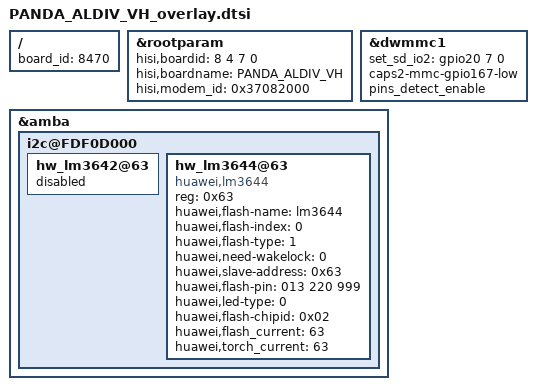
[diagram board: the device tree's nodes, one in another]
/**
 * Copyright (C) 2014 Hisilicon Ltd.
 *
 *  This program is free software; you can redistribute it and/or modify
 *  it under the terms of the GNU General Public License version 2 as
 *  publishhed by the Free Software Foundation.
 */


/include/ "PANDA_ALDPD_VB_overlay.dtsi"

/ {
    board_id = <8470>;
};

	&rootparam {
		hisi,boardid = <8 4 7 0>;
		hisi,boardname = "PANDA_ALDIV_VH";
		hisi,modem_id = <0x37082000>;
	};

	&dwmmc1 {
		set_sd_io2 = <&gpio20 7 0>;
		caps2-mmc-gpio167-low;
                /* enable nmcard 4pins detect */
                pins_detect_enable;
	};

&amba {
	i2c@FDF0D000 {
		hw_lm3642@63 {
			status = "disable";
		};
		hw_lm3644@63 {
			compatible = "huawei,lm3644";
			reg = <0x63>;
			huawei,flash-name = "lm3644";
			huawei,flash-index = <0>;
			huawei,flash-type = <1>;
			huawei,need-wakelock = <0>;
			huawei,slave-address = <0x63>;
			huawei,flash-pin = <013 220 999>;
			huawei,led-type = <0>; /* 1, dual tempature; 0, dual white */
			huawei,flash-chipid = <0x02>;
			huawei,flash_current = <63>; /*Default 729mA*/
			huawei,torch_current = <63>; /*Default 178.6mA*/
			status = "ok";
		};
	};
};
